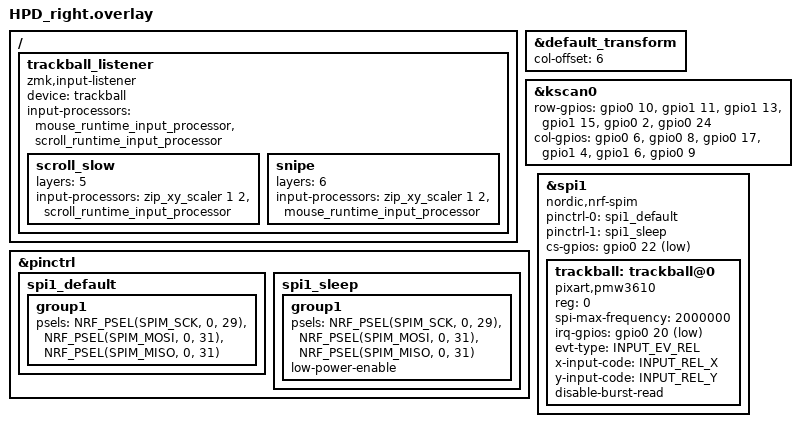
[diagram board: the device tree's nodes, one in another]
/*
 * Copyright (c) 2020 ZMK Contributors
 *
 * SPDX-License-Identifier: MIT
 */

#include "HPD.dtsi"

&default_transform {
    col-offset = <6>;
};

&kscan0 {
    row-gpios
        = <&gpio0 10 (GPIO_ACTIVE_HIGH | GPIO_PULL_DOWN)>
        , <&gpio1 11 (GPIO_ACTIVE_HIGH | GPIO_PULL_DOWN)>
        , <&gpio1 13  (GPIO_ACTIVE_HIGH | GPIO_PULL_DOWN)>
        , <&gpio1 15 (GPIO_ACTIVE_HIGH | GPIO_PULL_DOWN)>
        , <&gpio0 2 (GPIO_ACTIVE_HIGH | GPIO_PULL_DOWN)>
        , <&gpio0 24 (GPIO_ACTIVE_HIGH | GPIO_PULL_DOWN)>
        ;
    
	col-gpios
        =  <&gpio0 6  GPIO_ACTIVE_HIGH>
        ,  <&gpio0 8  GPIO_ACTIVE_HIGH>
        , <&gpio0 17  GPIO_ACTIVE_HIGH>
        , <&gpio1 4  GPIO_ACTIVE_HIGH>
        , <&gpio1 6  GPIO_ACTIVE_HIGH>
        , <&gpio0 9  GPIO_ACTIVE_HIGH>
		;
};

&pinctrl {
    spi1_default: spi1_default {
        group1 {
            psels = <NRF_PSEL(SPIM_SCK, 0, 29)>,
                <NRF_PSEL(SPIM_MOSI, 0, 31)>,
                <NRF_PSEL(SPIM_MISO, 0, 31)>;
        };
    };

    spi1_sleep: spi1_sleep {
        group1 {
            psels = <NRF_PSEL(SPIM_SCK, 0, 29)>,
                <NRF_PSEL(SPIM_MOSI, 0, 31)>,
                <NRF_PSEL(SPIM_MISO, 0, 31)>;
            low-power-enable;
        };
    };
};

&spi1 {
    status = "okay";
    compatible = "nordic,nrf-spim";
    pinctrl-0 = <&spi1_default>;
    pinctrl-1 = <&spi1_sleep>;
    pinctrl-names = "default", "sleep";
    cs-gpios = <&gpio0 22 GPIO_ACTIVE_LOW>;

    trackball: trackball@0 {
        status = "okay";
        compatible = "pixart,pmw3610";
        reg = <0>;
        spi-max-frequency = <2000000>;
        irq-gpios = <&gpio0 20 (GPIO_ACTIVE_LOW | GPIO_PULL_UP)>;
        evt-type = <INPUT_EV_REL>;
        x-input-code = <INPUT_REL_X>;
        y-input-code = <INPUT_REL_Y>;
        disable-burst-read;
    };
};

/ {
  trackball_listener {
    compatible = "zmk,input-listener";
    device = <&trackball>;
    input-processors = <&mouse_runtime_input_processor &scroll_runtime_input_processor>;

    scroll_slow {
        layers = <5>;
        input-processors = <&zip_xy_scaler 1 2 &scroll_runtime_input_processor>;
    };

    snipe {
        layers = <6>;
        input-processors = <&zip_xy_scaler 1 2 &mouse_runtime_input_processor>;
    };
  };
};
